# sam67_dmpac_wrap0_DMPAC_TOP_CFG_SLV_PAR_DOF_CFG_VP_MEM_MMRRAM_VBUSP_MMR_RAM register map
Vendor: Texas Instruments
Peripheral module from a debugger description file (folder J722S).
Registers are 32-bit, read-only, reset 0x0 unless marked. A register's access mark holds for its fields unless they carry their own. Offsets are as the file gives them; lines under a group give offsets from that group; [hi:lo] are bit positions; {n}, {i} and the like mark numbered series; 'fields as' and 'values as' point back to an identical list; <NAME> marks a mode.

## sam67_dmpac_wrap0_DMPAC_TOP_CFG_SLV_PAR_DOF_CFG_VP_MEM_MMRRAM_VBUSP_MMR_RAM
0x00 DMPAC_TOP__CFG_SLV__PAR_DOF__CFG_VP__MEM_MMR__MMRRAM_VBUSP__MMR_RAM_PSE_MEM_RAM — pse_mem_ram diagnostic read only port, vbusp will stall until RAM is available for read
  [31:0] DATA — Data read from RAM. RAM is wider than 32bit vbus. MMR reads are byte addresses into RAM where RAM Width is extended/zero padded to next pwr2.
{0x2000+0x2000*i} DMPAC_TOP__CFG_SLV__PAR_DOF__CFG_VP__MEM_MMR__MMRRAM_VBUSP__MMR_RAM_SRB_MEM{i}_RAM (i=0..15) — srb_mem{i}_ram diagnostic read only port, vbusp will stall until RAM is available for read
  fields as DMPAC_TOP__CFG_SLV__PAR_DOF__CFG_VP__MEM_MMR__MMRRAM_VBUSP__MMR_RAM_PSE_MEM_RAM
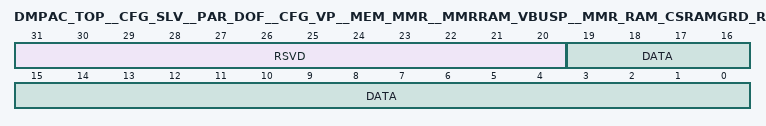
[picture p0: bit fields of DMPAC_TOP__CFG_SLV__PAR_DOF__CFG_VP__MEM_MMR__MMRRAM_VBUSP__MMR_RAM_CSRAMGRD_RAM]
0x22000 DMPAC_TOP__CFG_SLV__PAR_DOF__CFG_VP__MEM_MMR__MMRRAM_VBUSP__MMR_RAM_CSRAMGRD_RAM — csRamGrd_ram diagnostic read only port, vbusp will stall until RAM is available for read
  [31:20] RSVD — Always read as 0. Writes have no effect.
  [19:0] DATA — Data read from RAM
0x24000 DMPAC_TOP__CFG_SLV__PAR_DOF__CFG_VP__MEM_MMR__MMRRAM_VBUSP__MMR_RAM_CSRAMIIR_RAM — csRamIir_ram diagnostic read only port, vbusp will stall until RAM is available for read
  fields as DMPAC_TOP__CFG_SLV__PAR_DOF__CFG_VP__MEM_MMR__MMRRAM_VBUSP__MMR_RAM_PSE_MEM_RAM
0x28000 DMPAC_TOP__CFG_SLV__PAR_DOF__CFG_VP__MEM_MMR__MMRRAM_VBUSP__MMR_RAM_MFRAM0_RAM — mfRam0_ram diagnostic read only port, vbusp will stall until RAM is available for read
  fields as DMPAC_TOP__CFG_SLV__PAR_DOF__CFG_VP__MEM_MMR__MMRRAM_VBUSP__MMR_RAM_PSE_MEM_RAM
0x2C000 DMPAC_TOP__CFG_SLV__PAR_DOF__CFG_VP__MEM_MMR__MMRRAM_VBUSP__MMR_RAM_MFRAM1_RAM — mfRam1_ram diagnostic read only port, vbusp will stall until RAM is available for read
  fields as DMPAC_TOP__CFG_SLV__PAR_DOF__CFG_VP__MEM_MMR__MMRRAM_VBUSP__MMR_RAM_PSE_MEM_RAM
